# STM32H745_CM4 register map
File version: 2.0
CPU: CM4 r0p1, little endian, MPU, FPU, 4 interrupt priority bits
Registers are 32-bit, read-write, reset 0x0 unless marked. A register's access mark holds for its fields unless they carry their own. Offsets are from the block's base; [hi:lo] are bit positions; lines under a group give offsets from that group; {n}, {i} and the like mark numbered series.

## CRC — Cryptographic processor
Base 0x58024C00
0x00 DR reset 0xFFFFFFFF — Data register
  [31:0] DR — Data Register
0x00 DR8 8-bit reset 0xFF (alternate view of DR) — Data register - byte sized
  [7:0] DR8 — Data register bits
0x00 DR16 16-bit reset 0xFFFF (alternate view of DR) — Data register - half-word sized
  [15:0] DR16 — Data register bits
0x04 IDR — Independent Data register
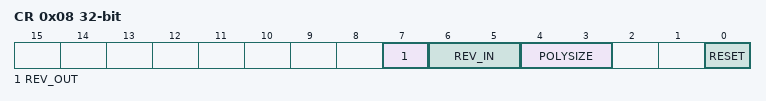
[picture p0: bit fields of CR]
0x08 CR — Control register
  [7] REV_OUT — Reverse output data
    0=Normal (Bit order not affected); 1=Reversed (Bit reversed output)
  [6:5] REV_IN — Reverse input data
    0=Normal (Bit order not affected); 1=Byte (Bit reversal done by byte); 2=HalfWord (Bit reversal done by half-word); 3=Word (Bit reversal done by word)
  [4:3] POLYSIZE — Polynomial size
    0=32-bit polynomial; 1=16-bit polynomial; 2=8-bit polynomial; 3=7-bit polynomial
  [0] RESET — RESET bit
    on write: 1=Resets the CRC calculation unit and sets the data register to 0xFFFF FFFF
0x10 INIT reset 0xFFFFFFFF — Initial CRC value
  [31:0] INIT — Programmable initial CRC value
0x14 POL reset 0x4C11DB7 — CRC polynomial
  [31:0] POL — Programmable polynomial

## DELAY_Block_SDMMC1
Base 0x52008000
Same registers: DELAY_Block_SDMMC2 0x48022800, DELAY_Block_QUADSPI 0x52006000
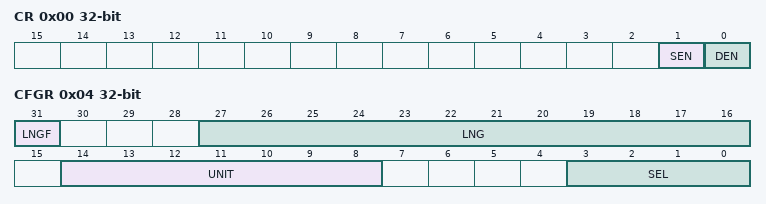
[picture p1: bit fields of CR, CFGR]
0x00 CR — DLYB control register
  [1] SEN — Sampler length enable bit
  [0] DEN — Delay block enable bit
0x04 CFGR — DLYB configuration register
  [31] LNGF — Length valid flag
  [27:16] LNG — Delay line length value
  [14:8] UNIT — Delay Defines the delay of a Unit delay cell
  [3:0] SEL — Select the phase for the Output clock

## OTG1_HS_HOST — USB 1 on the go high speed
Base 0x40040400
Same registers: OTG2_HS_HOST 0x40080400
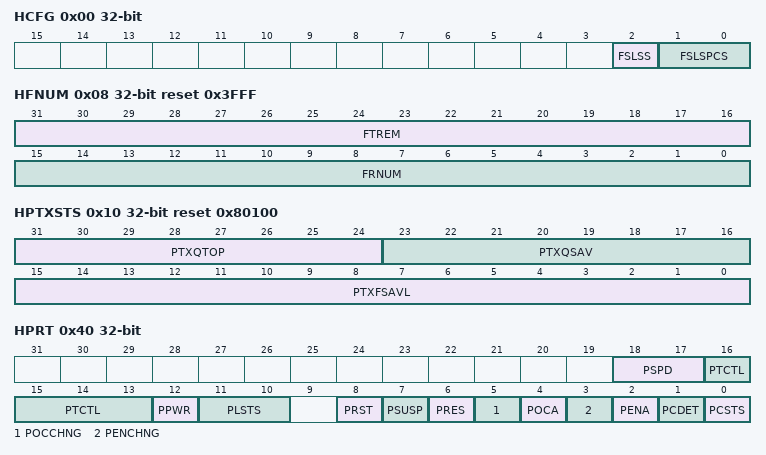
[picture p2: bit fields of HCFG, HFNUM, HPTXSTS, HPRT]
0x00 HCFG access per field — OTG_HS host configuration register
  [2] FSLSS ro — FS- and LS-only support
  [1:0] FSLSPCS rw — FS/LS PHY clock select
0x04 HFIR reset 0xEA60 — OTG_HS Host frame interval register
  [15:0] FRIVL — Frame interval
0x08 HFNUM ro reset 0x3FFF — OTG_HS host frame number/frame time remaining register
  [31:16] FTREM — Frame time remaining
  [15:0] FRNUM — Frame number
0x10 HPTXSTS access per field reset 0x80100 — OTG_HS_Host periodic transmit FIFO/queue status register
  [31:24] PTXQTOP ro — Top of the periodic transmit request queue
  [23:16] PTXQSAV ro — Periodic transmit request queue space available
  [15:0] PTXFSAVL rw — Periodic transmit data FIFO space available
0x14 HAINT ro — OTG_HS Host all channels interrupt register
  [15:0] HAINT — Channel interrupts
0x18 HAINTMSK — OTG_HS host all channels interrupt mask register
  [15:0] HAINTM — Channel interrupt mask
0x40 HPRT access per field — OTG_HS host port control and status register
  [18:17] PSPD ro — Port speed
  [16:13] PTCTL rw — Port test control
  [12] PPWR rw — Port power
  [11:10] PLSTS ro — Port line status
  [8] PRST rw — Port reset
  [7] PSUSP rw — Port suspend
  [6] PRES rw — Port resume
  [5] POCCHNG rw — Port overcurrent change
  [4] POCA ro — Port overcurrent active
  [3] PENCHNG rw — Port enable/disable change
  [2] PENA rw — Port enable
  [1] PCDET rw — Port connect detected
  [0] PCSTS ro — Port connect status
{0x100+0x20*i} HC{i} (i=0..15) group — Host channel
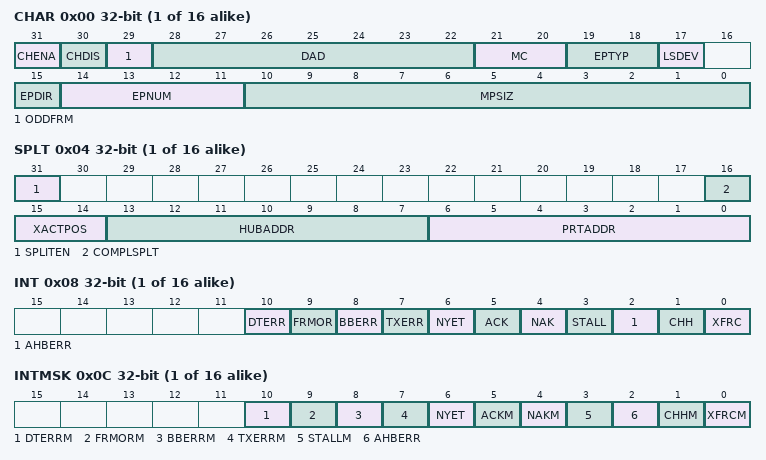
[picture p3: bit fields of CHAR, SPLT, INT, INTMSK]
  0x00 CHAR — OTG_HS host channel-0 characteristics register
    [31] CHENA — Channel enable
    [30] CHDIS — Channel disable
    [29] ODDFRM — Odd frame
    [28:22] DAD — Device address
    [21:20] MC — Multi Count (MC) / Error Count (EC)
    [19:18] EPTYP — Endpoint type
    [17] LSDEV — Low-speed device
    [15] EPDIR — Endpoint direction
    [14:11] EPNUM — Endpoint number
    [10:0] MPSIZ — Maximum packet size
  0x04 SPLT — OTG_HS host channel-0 split control register
    [31] SPLITEN — Split enable
    [16] COMPLSPLT — Do complete split
    [15:14] XACTPOS
    [13:7] HUBADDR — Hub address
    [6:0] PRTADDR — Port address
  0x08 INT — OTG_HS host channel-11 interrupt register
    [10] DTERR — Data toggle error
    [9] FRMOR — Frame overrun
    [8] BBERR — Babble error
    [7] TXERR — Transaction error
    [6] NYET — Response received interrupt
    [5] ACK — ACK response received/transmitted interrupt
    [4] NAK — NAK response received interrupt
    [3] STALL — STALL response received interrupt
    [2] AHBERR — AHB error
    [1] CHH — Channel halted
    [0] XFRC — Transfer completed
  0x0C INTMSK — OTG_HS host channel-11 interrupt mask register
    [10] DTERRM — Data toggle error mask
    [9] FRMORM — Frame overrun mask
    [8] BBERRM — Babble error mask
    [7] TXERRM — Transaction error mask
    [6] NYET — response received interrupt mask
    [5] ACKM — ACK response received/transmitted interrupt mask
    [4] NAKM — NAK response received interrupt mask
    [3] STALLM — STALL response received interrupt mask
    [2] AHBERR — AHB error
    [1] CHHM — Channel halted mask
    [0] XFRCM — Transfer completed mask
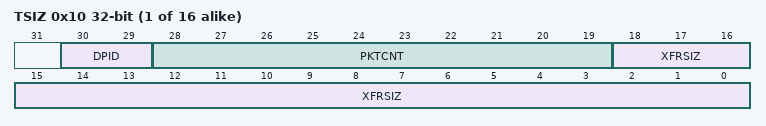
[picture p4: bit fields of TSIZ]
  0x10 TSIZ — OTG_HS host channel-11 transfer size register
    [30:29] DPID — Data PID
    [28:19] PKTCNT — Packet count
    [18:0] XFRSIZ — Transfer size
  0x14 DMA — OTG_HS host channel-0 DMA address register
    [31:0] DMAADDR — DMA address
